AUTOSAR XML (schema 4-0-3)
standard types defined: uint8, Boolean, UInt16, UInt32, UInt8
package /AUTOSAR_Platform/DataConstrs
  range DC_Boolean: raw 0..1
  range DC_UInt16: raw 0..65535
  range DC_UInt8: raw 0..255
package /PATAC/Facility/DataTypes/Implementation
  compu method COMPU_Boolean: 0=FALSE, 1=TRUE
  unit NoUnit: factor-si-to-unit=1, offset-si-to-unit=0
package /PATAC/MSM/ComponentTypes
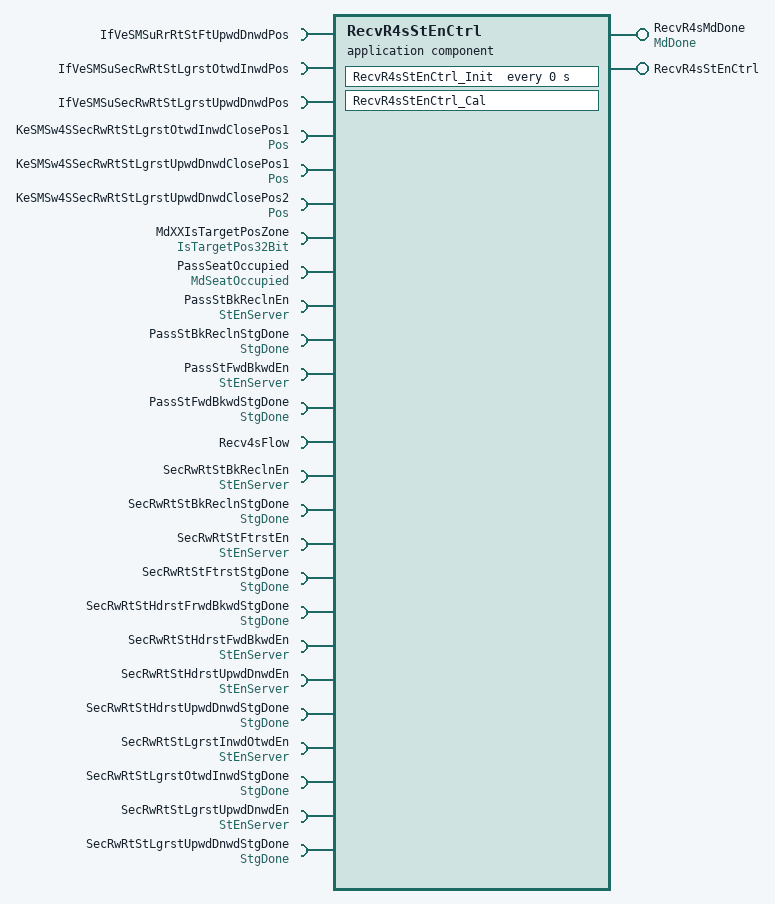
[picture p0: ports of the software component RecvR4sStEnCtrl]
  application sw component type RecvR4sStEnCtrl
    provide port RecvR4sMdDone: nonqueued-sender-com-spec{data-element=MdDone/Val, init-value=0}, provided-interface=MdDone
    provide port RecvR4sStEnCtrl: server-com-spec{operation=RecvR4sStEnCtrl/Cal, queue-length=1}, provided-interface=RecvR4sStEnCtrl
    25 x require port:
      IfVeSMSuRrRtStFtUpwdDnwdPos: nonqueued-receiver-com-spec{data-element=IfVeSMSuRrRtStFtUpwdDnwdPos/Val, filter=data-filter-type=ALWAYS, init-value=0}, required-interface=IfVeSMSuRrRtStFtUpwdDnwdPos
      IfVeSMSuSecRwRtStLgrstOtwdInwdPos: nonqueued-receiver-com-spec{data-element=IfVeSMSuSecRwRtStLgrstOtwdInwdPos/Val, filter=data-filter-type=ALWAYS, init-value=0}, required-interface=IfVeSMSuSecRwRtStLgrstOtwdInwdPos
      IfVeSMSuSecRwRtStLgrstUpwdDnwdPos: nonqueued-receiver-com-spec{data-element=IfVeSMSuSecRwRtStLgrstUpwdDnwdPos/Val, filter=data-filter-type=ALWAYS, init-value=0}, required-interface=IfVeSMSuSecRwRtStLgrstUpwdDnwdPos
      KeSMSw4SSecRwRtStLgrstOtwdInwdClosePos1: parameter-require-com-spec{init-value=0, parameter=Val}, required-interface=Pos
      KeSMSw4SSecRwRtStLgrstUpwdDnwdClosePos1: parameter-require-com-spec{init-value=0, parameter=Val}, required-interface=Pos
      KeSMSw4SSecRwRtStLgrstUpwdDnwdClosePos2: parameter-require-com-spec{init-value=0, parameter=Val}, required-interface=Pos
      MdXXIsTargetPosZone: nonqueued-receiver-com-spec{data-element=IsTargetPos32Bit/Val, filter=data-filter-type=ALWAYS, init-value=0}, required-interface=IsTargetPos32Bit
      PassSeatOccupied: nonqueued-receiver-com-spec{data-element=MdSeatOccupied/Val, filter=data-filter-type=ALWAYS, init-value=0}, required-interface=MdSeatOccupied
      PassStBkReclnEn: required-com-specs=[Clear, Get, Set], required-interface=StEnServer
      PassStBkReclnStgDone: nonqueued-receiver-com-spec{data-element=StgDone/Val, filter=data-filter-type=ALWAYS, init-value=0}, required-interface=StgDone
      PassStFwdBkwdEn: required-com-specs=[Clear, Get, Set], required-interface=StEnServer
      PassStFwdBkwdStgDone: nonqueued-receiver-com-spec{data-element=StgDone/Val, filter=data-filter-type=ALWAYS, init-value=0}, required-interface=StgDone
      Recv4sFlow: client-com-spec=Recv4sFlow/Cal, required-interface=Recv4sFlow
      SecRwRtStBkReclnEn: required-com-specs=[Clear, Get, Set], required-interface=StEnServer
      SecRwRtStBkReclnStgDone: nonqueued-receiver-com-spec{data-element=StgDone/Val, filter=data-filter-type=ALWAYS, init-value=0}, required-interface=StgDone
      SecRwRtStFtrstEn: required-com-specs=[Clear, Get, Set], required-interface=StEnServer
      SecRwRtStFtrstStgDone: nonqueued-receiver-com-spec{data-element=StgDone/Val, filter=data-filter-type=ALWAYS, init-value=0}, required-interface=StgDone
      SecRwRtStHdrstFrwdBkwdStgDone: nonqueued-receiver-com-spec{data-element=StgDone/Val, filter=data-filter-type=ALWAYS, init-value=0}, required-interface=StgDone
      SecRwRtStHdrstFwdBkwdEn: required-com-specs=[Clear, Get, Set], required-interface=StEnServer
      SecRwRtStHdrstUpwdDnwdEn: required-com-specs=[Clear, Get, Set], required-interface=StEnServer
      SecRwRtStHdrstUpwdDnwdStgDone: nonqueued-receiver-com-spec{data-element=StgDone/Val, filter=data-filter-type=ALWAYS, init-value=0}, required-interface=StgDone
      SecRwRtStLgrstInwdOtwdEn: required-com-specs=[Clear, Get, Set], required-interface=StEnServer
      SecRwRtStLgrstOtwdInwdStgDone: nonqueued-receiver-com-spec{data-element=StgDone/Val, filter=data-filter-type=ALWAYS, init-value=0}, required-interface=StgDone
      SecRwRtStLgrstUpwdDnwdEn: required-com-specs=[Clear, Get, Set], required-interface=StEnServer
      SecRwRtStLgrstUpwdDnwdStgDone: nonqueued-receiver-com-spec{data-element=StgDone/Val, filter=data-filter-type=ALWAYS, init-value=0}, required-interface=StgDone
    behavior RecvR4sStEnCtrl_InternalBehavior
      operation invoked event OIT_RecvR4sStEnCtrl_Cal_RecvR4sStEnCtrl_Cal: start-on-event=RecvR4sStEnCtrl_Cal, operation=RecvR4sStEnCtrl.Cal
      timing event RecvR4sStEnCtrl_InitEvent: start-on-event=RecvR4sStEnCtrl_Init, period=0
      runnable RecvR4sStEnCtrl_Cal
        data-receive-point-by-arguments:
          13 x access:
            REC_IfVeSMSuRrRtStFtUpwdDnwdPos_Val: accessed-variable=IfVeSMSuRrRtStFtUpwdDnwdPos.Val
            REC_IfVeSMSuSecRwRtStLgrstOtwdInwdPos_Val: accessed-variable=IfVeSMSuSecRwRtStLgrstOtwdInwdPos.Val
            REC_IfVeSMSuSecRwRtStLgrstUpwdDnwdPos_Val: accessed-variable=IfVeSMSuSecRwRtStLgrstUpwdDnwdPos.Val
            REC_MdXXIsTargetPosZone_Val: accessed-variable=MdXXIsTargetPosZone.Val
            REC_PassSeatOccupied_Val: accessed-variable=PassSeatOccupied.Val
            REC_PassStBkReclnStgDone_Val: accessed-variable=PassStBkReclnStgDone.Val
            REC_PassStFwdBkwdStgDone_Val: accessed-variable=PassStFwdBkwdStgDone.Val
            REC_SecRwRtStBkReclnStgDone_Val: accessed-variable=SecRwRtStBkReclnStgDone.Val
            REC_SecRwRtStFtrstStgDone_Val: accessed-variable=SecRwRtStFtrstStgDone.Val
            REC_SecRwRtStHdrstFrwdBkwdStgDone_Val: accessed-variable=SecRwRtStHdrstFrwdBkwdStgDone.Val
            REC_SecRwRtStHdrstUpwdDnwdStgDone_Val: accessed-variable=SecRwRtStHdrstUpwdDnwdStgDone.Val
            REC_SecRwRtStLgrstOtwdInwdStgDone_Val: accessed-variable=SecRwRtStLgrstOtwdInwdStgDone.Val
            REC_SecRwRtStLgrstUpwdDnwdStgDone_Val: accessed-variable=SecRwRtStLgrstUpwdDnwdStgDone.Val
        data-send-points:
          access SEND_RecvR4sMdDone_Val: accessed-variable=RecvR4sMdDone.Val
        parameter access PA_KeSMSw4SSecRwRtStLgrstOtwdInwdClosePos1_Val: accessed-parameter=KeSMSw4SSecRwRtStLgrstOtwdInwdClosePos1.Val
        parameter access PA_KeSMSw4SSecRwRtStLgrstUpwdDnwdClosePos1_Val: accessed-parameter=KeSMSw4SSecRwRtStLgrstUpwdDnwdClosePos1.Val
        parameter access PA_KeSMSw4SSecRwRtStLgrstUpwdDnwdClosePos2_Val: accessed-parameter=KeSMSw4SSecRwRtStLgrstUpwdDnwdClosePos2.Val
        17 x sync call, all with timeout=0:
          SC_PassStBkReclnEn_Clear: operation=PassStBkReclnEn.Clear
          SC_PassStBkReclnEn_Set: operation=PassStBkReclnEn.Set
          SC_PassStFwdBkwdEn_Clear: operation=PassStFwdBkwdEn.Clear
          SC_PassStFwdBkwdEn_Set: operation=PassStFwdBkwdEn.Set
          SC_Recv4sFlow_Cal: operation=Recv4sFlow.Cal
          SC_SecRwRtStBkReclnEn_Clear: operation=SecRwRtStBkReclnEn.Clear
          SC_SecRwRtStBkReclnEn_Set: operation=SecRwRtStBkReclnEn.Set
          SC_SecRwRtStFtrstEn_Clear: operation=SecRwRtStFtrstEn.Clear
          SC_SecRwRtStFtrstEn_Set: operation=SecRwRtStFtrstEn.Set
          SC_SecRwRtStHdrstFwdBkwdEn_Clear: operation=SecRwRtStHdrstFwdBkwdEn.Clear
          SC_SecRwRtStHdrstFwdBkwdEn_Set: operation=SecRwRtStHdrstFwdBkwdEn.Set
          SC_SecRwRtStHdrstUpwdDnwdEn_Clear: operation=SecRwRtStHdrstUpwdDnwdEn.Clear
          SC_SecRwRtStHdrstUpwdDnwdEn_Set: operation=SecRwRtStHdrstUpwdDnwdEn.Set
          SC_SecRwRtStLgrstInwdOtwdEn_Clear: operation=SecRwRtStLgrstInwdOtwdEn.Clear
          SC_SecRwRtStLgrstInwdOtwdEn_Set: operation=SecRwRtStLgrstInwdOtwdEn.Set
          SC_SecRwRtStLgrstUpwdDnwdEn_Clear: operation=SecRwRtStLgrstUpwdDnwdEn.Clear
          SC_SecRwRtStLgrstUpwdDnwdEn_Set: operation=SecRwRtStLgrstUpwdDnwdEn.Set
      runnable RecvR4sStEnCtrl_Init
        parameter access PA_KeSMSw4SSecRwRtStLgrstOtwdInwdClosePos1_Val: accessed-parameter=KeSMSw4SSecRwRtStLgrstOtwdInwdClosePos1.Val
        parameter access PA_KeSMSw4SSecRwRtStLgrstUpwdDnwdClosePos1_Val: accessed-parameter=KeSMSw4SSecRwRtStLgrstUpwdDnwdClosePos1.Val
        parameter access PA_KeSMSw4SSecRwRtStLgrstUpwdDnwdClosePos2_Val: accessed-parameter=KeSMSw4SSecRwRtStLgrstUpwdDnwdClosePos2.Val
  swc implementation RecvR4sStEnCtrl_Implementation: behavior=RecvR4sStEnCtrl_InternalBehavior
    code-descriptors:
      code Default: artifact-descriptors=autosar-engineering-object={short-label=Default, category=SWSRC}
package /PATAC/MSM/ModeAdjust/CalPortInterface
  parameter interface Pos
    parameter data prototype Val: sw-calibration-access=READ-WRITE, type=UInt16
package /PATAC/MSM/ModeAdjust/PortInterface
  client server interface Recv4sFlow
    operation Cal
      19 x arg, all with server-argument-impl-policy=USE-ARGUMENT-TYPE:
        LgrstUpwdDnwdPos: type=UInt16, direction=IN
        LgrstOtwdInwdPos: type=UInt16, direction=IN
        FtUpwdDnwdPos: type=UInt16, direction=IN
        CloseDnwdPos1: type=UInt16, direction=IN
        CloseDnwdPos2: type=UInt16, direction=IN
        CloseOtwdPos1: type=UInt16, direction=IN
        LgrstInwdStgDone: type=Boolean, direction=IN
        LgrstUpwdStgDone: type=Boolean, direction=IN
        FtrstStgDone: type=Boolean, direction=IN
        BkReclnStgDone: type=Boolean, direction=IN
        HdrstFwdBkwdStgDone: type=Boolean, direction=IN
        HdrstupwdDnwdStgDone: type=Boolean, direction=IN
        Failflg: type=Boolean, direction=OUT
        LgrstInwdOtwdEn: type=Boolean, direction=OUT
        LgrstUpwdDnwdEn: type=Boolean, direction=OUT
        FtrstEn: type=Boolean, direction=OUT
        BkReclnEn: type=Boolean, direction=OUT
        HdrstFrwdBkwdEn: type=Boolean, direction=OUT
        HdrstUpwdDnwdEn: type=Boolean, direction=OUT
  client server interface RecvR4sStEnCtrl
    operation Cal
  client server interface StEnServer
    operation Clear
      arg data: type=UInt8, direction=IN, server-argument-impl-policy=USE-ARGUMENT-TYPE
    operation Get
      arg data: type=UInt32, direction=OUT, server-argument-impl-policy=USE-ARGUMENT-TYPE
    operation Set
      arg data: type=UInt8, direction=IN, server-argument-impl-policy=USE-ARGUMENT-TYPE
  4 x sender receiver interface:
    IsTargetPos32Bit: invalidation-policy{data-element=IsTargetPos32Bit/Val, handle-invalid=DONT-INVALIDATE}
      data Val: type=UInt32
    MdDone: invalidation-policy{data-element=MdDone/Val, handle-invalid=DONT-INVALIDATE}
      data Val: type=UInt8
    MdSeatOccupied: invalidation-policy{data-element=MdSeatOccupied/Val, handle-invalid=DONT-INVALIDATE}
      data Val: type=Boolean
    StgDone: invalidation-policy{data-element=StgDone/Val, handle-invalid=DONT-INVALIDATE}
      data Val: type=Boolean
package /PATAC/MSM/PortInterfaces
  sender receiver interface IfVeSMSuRrRtStFtUpwdDnwdPos: invalidation-policy{data-element=IfVeSMSuRrRtStFtUpwdDnwdPos/Val, handle-invalid=DONT-INVALIDATE}
    data Val: type=UInt16
  sender receiver interface IfVeSMSuSecRwRtStLgrstOtwdInwdPos: invalidation-policy{data-element=IfVeSMSuSecRwRtStLgrstOtwdInwdPos/Val, handle-invalid=DONT-INVALIDATE}
    data Val: type=UInt16
  sender receiver interface IfVeSMSuSecRwRtStLgrstUpwdDnwdPos: invalidation-policy{data-element=IfVeSMSuSecRwRtStLgrstUpwdDnwdPos/Val, handle-invalid=DONT-INVALIDATE}
    data Val: type=UInt16
